# N32L406 register map
Vendor: Nationstech Ltd.; File version: 1.0
Registers are 32-bit, read-write, reset 0x0 unless marked. A register's access mark holds for its fields unless they carry their own. Offsets are from the block's base; [hi:lo] are bit positions.

## FPE — System Control registers for the FP extension
Base 0xE000EF34
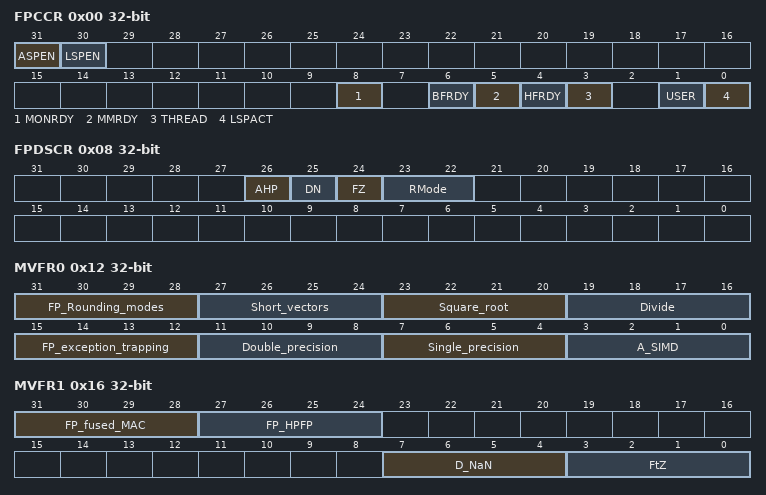
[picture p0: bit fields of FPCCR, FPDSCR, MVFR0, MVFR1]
0x00 FPCCR — Holds control data for the floating-point unit
  [31] ASPEN — When this bit is set to 1, execution of a floating-point instruction sets the CONTROL.FPCA bit to 1
  [30] LSPEN — Enables lazy context save of FP state
    0=Disable; 1=Enable
  [8] MONRDY — Indicates whether the software executing when the processor allocated the FP stack frame was able to set the DebugMonitor exception to pending
    0=Not_Able; 1=Able
  [6] BFRDY — Indicates whether the software executing when the processor allocated the FP stack frame was able to set the BusFault exception to pending
    0=Not_Able; 1=Able
  [5] MMRDY — Indicates whether the software executing when the processor allocated the FP stack frame was able to set the MemManage exception to pending
    0=Not_Able; 1=Able
  [4] HFRDY — Indicates whether the software executing when the processor allocated the FP stack frame was able to set the HardFault exception to pending
    0=Not_Able; 1=Able
  [3] THREAD — Indicates the processor mode when it allocated the FP stack frame
    0=Handler; 1=Thread
  [1] USER — Indicates the privilege level of the software executing when the processor allocated the FP stack frame
    0=Privileged; 1=Unprivileged
  [0] LSPACT — Indicates whether Lazy preservation of the FP state is active
    0=Not_Active; 1=Active
0x04 FPCAR — Holds the location of the unpopulated floating-point register space allocated on an exception stack frame
0x08 FPDSCR — Holds the default values for the floating-point status control data that the processor assigns to the FPSCR when it creates a new floating-point context
  [26] AHP — Default value for FPSCR.AHP
  [25] DN — Default value for FPSCR.DN
  [24] FZ — Default value for FPSCR.FZ
  [23:22] RMode — Default value for FPSCR.RMode
0x12 MVFR0 ro — Describes the features provided by the Floating-point extension
  [31:28] FP_Rounding_modes — Indicates the rounding modes supported by the FP floating-point hardware
    1=Supported
  [27:24] Short_vectors — Indicates the hardware support for FP short vectors
    0=Not_Supported
  [23:20] Square_root — Indicates the hardware support for FP square root operations
    1=Supported
  [19:16] Divide — Indicates the hardware support for FP divide operations
    1=Supported
  [15:12] FP_exception_trapping — Indicates whether the FP hardware implementation supports exception trapping
    0=Not_Supported
  [11:8] Double_precision — Indicates the hardware support for FP double-precision operations
    0=Not_Supported
  [7:4] Single_precision — Indicates the hardware support for FP single-precision operations
    2=Supported
  [3:0] A_SIMD — Indicates the size of the FP register bank
    1=_16x64
0x16 MVFR1 ro — Describes the features provided by the Floating-point extension
  [all] fields
    1=Supported
  [31:28] FP_fused_MAC — Indicates whether the FP supports fused multiply accumulate operations
  [27:24] FP_HPFP — Indicates whether the FP supports half-precision floating-point conversion operations
  [7:4] D_NaN — Indicates whether the FP hardware implementation supports only the Default NaN mode
  [3:0] FtZ — Indicates whether the FP hardware implementation supports only the Flush-to-Zero mode of operation

## SysTick — System Timer registers
Base 0xE000E010
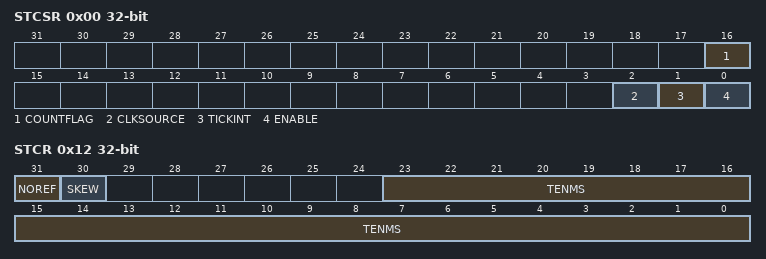
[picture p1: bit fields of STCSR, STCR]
0x00 STCSR — Controls the system timer and provides status data
  [16] COUNTFLAG — Indicates whether the counter has counted to 0 since the last read of this register
    0=not_counted_to_0; 1=counted_to_0
  [2] CLKSOURCE — Indicates the SysTick clock source
    0=External_clock; 1=Processor_clock
  [1] TICKINT — Indicates whether counting to 0 causes the status of the SysTick exception to change to pending
    0=Does_not_affect_exception_status; 1=Changes_exception_status
  [0] ENABLE — Indicates the enabled status of the SysTick counter
    0=Counter_disabled; 1=Counter_operating
0x04 STRVR — Sets or reads the reload value of the SYST_CVR register
  [23:0] RELOAD — The value to load into the SYST_CVR register when the counter reaches 0
0x08 STCVR — Reads or clears the current counter value
  [23:0] CURRENT — This is the value of the counter at the time it is sampled
0x12 STCR ro — Reads the calibration value and parameters for SysTick
  [31] NOREF — Indicates whether the IMPLEMENTATION DEFINED reference clock is provided
    0=Implemented; 1=Not_implemented
  [30] SKEW — Indicates whether the 10ms calibration value is exact
    0=Exact; 1=Inexact
  [23:0] TENMS — Optionally, holds a reload value to be used for 10ms (100Hz) timing, subject to system clock skew errors
